# nrf7120_enga_wificore register map
Vendor: Nordic Semiconductor; Series: nrf71; File version: 1
Registers are 32-bit, read-write, reset 0x0 unless marked. A register's access mark holds for its fields unless they carry their own. Offsets are from the block's base; [hi:lo] are bit positions; lines under a group give offsets from that group; {n}, {i} and the like mark numbered series; 'fields as' and 'values as' point back to an identical list.

## ANTSWC — Antenna switch controller
Base 0x4800D000
0x400 ERRORSTATUS group — Unspecified
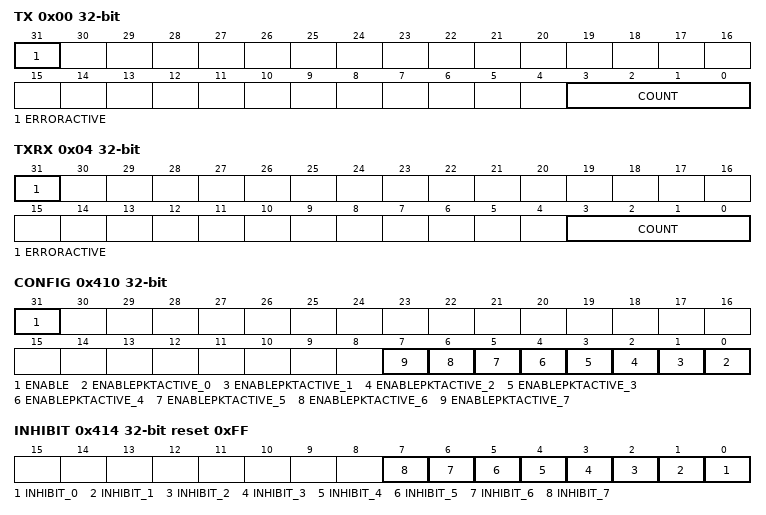
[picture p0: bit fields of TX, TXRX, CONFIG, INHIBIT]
  0x00 TX — Concurrent TX error condition
    [31] ERRORACTIVE ro — Concurrent TX error condition is active
    [3:0] COUNT — Count of concurrent TX error conditions detected
  0x04 TXRX — Concurrent TX-RX error condition
    [31] ERRORACTIVE ro — Concurrent TX-RX error condition is active
    [3:0] COUNT — Count of concurrent TX-RX error conditions detected
  0x08 ERRORPORT — Indicates which ports are in error
    [7:0] ERRORPORT — Bitfield indicating the ports in error during the last error condition.
0x410 CONFIG — Antenna switch controller enable / software reset
  [31] ENABLE — Enable antenna switch module.
    0=Disable (Antenna Switch Controller disabled - all outputs held low); 1=Enable (Antenna Switch Controller enabled)
  [n] ENABLEPKTACTIVE_{n} (n=0..7) — Bitfield indicating whether ANTSWC listens to PktActive on radio port i.
    0=Ignore PktActive on the corresponding radio port; 1=Respect (Use PktActive on the corresponding radio port for antenna switch selection)
0x414 INHIBIT reset 0xFF
  [all] fields
    0=Inhibit connection of antenna to the corresponding radio; 1=Enable antenna to be connected to the corresponding radio
  [n] INHIBIT_{n} (n=0..7) — Bitfield of 8 separate bits indicating whether connection of the antenna to radio on radio port i is enabled or inhibited.

## GLOBAL_DPPIC00 — Distributed programmable peripheral interconnect controller 0
Base 0x50042000; alternate view of GLOBAL_USBHSCORE
Same registers: GLOBAL_DPPIC10 0x50082000, GLOBAL_DPPIC20 0x500C2000, GLOBAL_DPPIC30 0x50102000
{0x0+8i} TASKS_CHG[{i}] (i=0..5) group — Channel group tasks
  0x00 EN wo — Description cluster: Enable channel group n
    [0] EN — Enable channel group n
      1=Trigger task
  0x04 DIS wo — Description cluster: Disable channel group n
    [0] DIS — Disable channel group n
      1=Trigger task
{0x80+8i} SUBSCRIBE_CHG[{i}] (i=0..5) group — Subscribe configuration for tasks
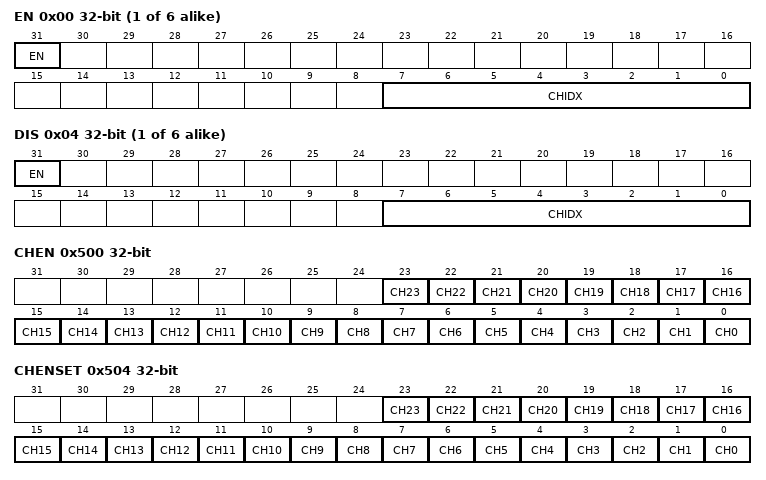
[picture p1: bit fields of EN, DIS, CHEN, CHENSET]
  0x00 EN — Description cluster: Subscribe configuration for task CHG[n].EN
    [31] EN
      0=Disabled (Disable subscription); 1=Enabled (Enable subscription)
    [7:0] CHIDX — DPPI channel that task CHG[n].EN will subscribe to
  0x04 DIS — Description cluster: Subscribe configuration for task CHG[n].DIS
    [31] EN
      values as SUBSCRIBE_CHG[0].EN.EN
    [7:0] CHIDX — DPPI channel that task CHG[n].DIS will subscribe to
0x500 CHEN — Channel enable register
  [all] fields
    0=Disabled (Disable channel); 1=Enabled (Enable channel)
  [n] CH{n} (n=0..23) — Enable or disable channel {n}
0x504 CHENSET write-1-sets — Channel enable set register
  [all] fields
    on read: 0=Disabled (Read: Channel disabled); 1=Enabled (Read: Channel enabled) | on write: 1=Set (Write: Enable channel)
  [n] CH{n} (n=0..23) — Channel {n} enable set register. Writing 0 has no effect.
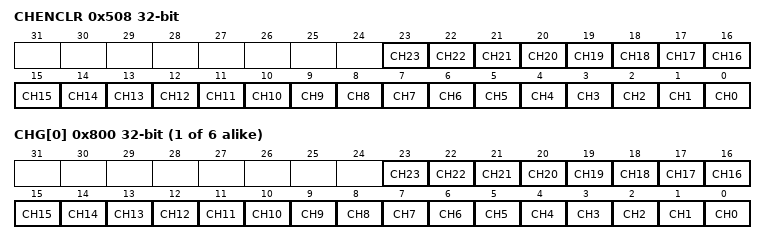
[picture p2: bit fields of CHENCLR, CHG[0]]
0x508 CHENCLR write-1-clears — Channel enable clear register
  [all] fields
    on read: 0=Disabled (Read: Channel disabled); 1=Enabled (Read: Channel enabled) | on write: 1=Clear (Write: Disable channel)
  [n] CH{n} (n=0..23) — Channel {n} enable clear register. Writing 0 has no effect.
{0x800+4i} CHG[{i}] (i=0..5) — Description collection: Channel group n Note: Writes to this register are ignored if either SUBSCRIBE_CHG[n].EN or SUBSCRIBE_CHG[n].DIS is enabled
  [all] fields
    0=Excluded; 1=Included
  [n] CH{n} (n=0..23) — Include or exclude channel {n}

## GLOBAL_PPIB00 — PPIB APB registers 0
Base 0x50044000
Same registers: GLOBAL_PPIB01 0x50045000, GLOBAL_PPIB10 0x50083000, GLOBAL_PPIB11 0x50084000, GLOBAL_PPIB20 0x500C3000, GLOBAL_PPIB21 0x500C4000, GLOBAL_PPIB22 0x500C5000, GLOBAL_PPIB30 0x50103000
{0x0+4i} TASKS_SEND[{i}] (i=0..31) wo — Description collection: This task is unused, but the PPIB provides the SUBSCRIBE task to connect SEND [n] task.
  [0] TASKS_SEND — This task is unused, but the PPIB provides the SUBSCRIBE task to connect SEND [n] task.
    1=Trigger task
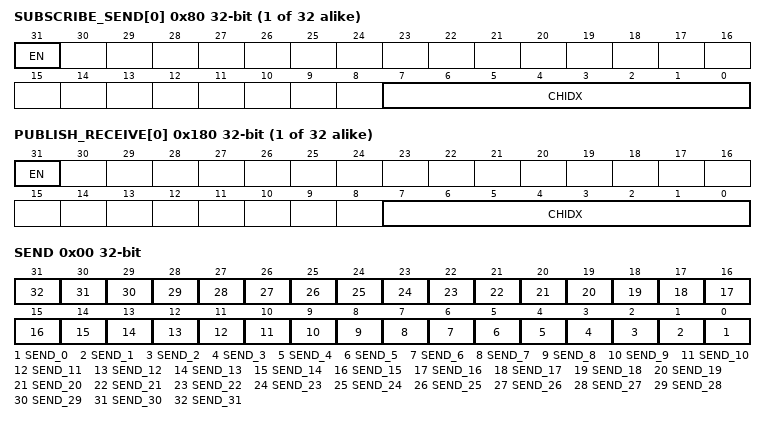
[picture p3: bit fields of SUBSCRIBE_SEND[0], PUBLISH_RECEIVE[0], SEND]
{0x80+4i} SUBSCRIBE_SEND[{i}] (i=0..31) — Description collection: Subscribe configuration for task SEND[n]
  [31] EN
    0=Disabled (Disable subscription); 1=Enabled (Enable subscription)
  [7:0] CHIDX — DPPI channel that task SEND[n] will subscribe to
{0x100+4i} EVENTS_RECEIVE[{i}] (i=0..31) — Description collection: This event is unused, but the PPIB provides the PUBLISH event to connect RECEIVE [n] event.
  [0] EVENTS_RECEIVE — This event is unused, but the PPIB provides the PUBLISH event to connect RECEIVE [n] event.
    0=NotGenerated (Event not generated); 1=Generated (Event generated)
{0x180+4i} PUBLISH_RECEIVE[{i}] (i=0..31) — Description collection: Publish configuration for event RECEIVE[n]
  [31] EN
    0=Disabled (Disable publishing); 1=Enabled (Enable publishing)
  [7:0] CHIDX — DPPI channel that event RECEIVE[n] will publish to
0x400 OVERFLOW group — Unspecified
  0x00 SEND — The task overflow for SEND tasks using SUBSCRIBE_SEND. Write 0 to clear.
    [all] fields
      1=Overflow (Task overflow is happened.); 0=NoOverflow (Task overflow is not happened.)
    [n] SEND_{n} (n=0..31) — The status for tasks overflow at SUBSCRIBE_SEND[{n}].

## Notices in the file
Copyright (c) 2010 - 2025, Nordic Semiconductor ASA All rights reserved.
SPDX-License-Identifier: BSD-3-Clause
Redistribution and use in source and binary forms, with or without
modification, are permitted provided that the following conditions are met:
1. Redistributions of source code must retain the above copyright notice, this
list of conditions and the following disclaimer.
2. Redistributions in binary form must reproduce the above copyright
notice, this list of conditions and the following disclaimer in the
documentation and/or other materials provided with the distribution.
3. Neither the name of Nordic Semiconductor ASA nor the names of its
contributors may be used to endorse or promote products derived from this
software without specific prior written permission.
THIS SOFTWARE IS PROVIDED BY THE COPYRIGHT HOLDERS AND CONTRIBUTORS "AS IS"
AND ANY EXPRESS OR IMPLIED WARRANTIES, INCLUDING, BUT NOT LIMITED TO, THE
IMPLIED WARRANTIES OF MERCHANTABILITY, AND FITNESS FOR A PARTICULAR PURPOSE
ARE DISCLAIMED. IN NO EVENT SHALL NORDIC SEMICONDUCTOR ASA OR CONTRIBUTORS BE
LIABLE FOR ANY DIRECT, INDIRECT, INCIDENTAL, SPECIAL, EXEMPLARY, OR
CONSEQUENTIAL DAMAGES (INCLUDING, BUT NOT LIMITED TO, PROCUREMENT OF
SUBSTITUTE GOODS OR SERVICES; LOSS OF USE, DATA, OR PROFITS; OR BUSINESS
INTERRUPTION) HOWEVER CAUSED AND ON ANY THEORY OF LIABILITY, WHETHER IN
CONTRACT, STRICT LIABILITY, OR TORT (INCLUDING NEGLIGENCE OR OTHERWISE)
ARISING IN ANY WAY OUT OF THE USE OF THIS SOFTWARE, EVEN IF ADVISED OF THE
POSSIBILITY OF SUCH DAMAGE.
